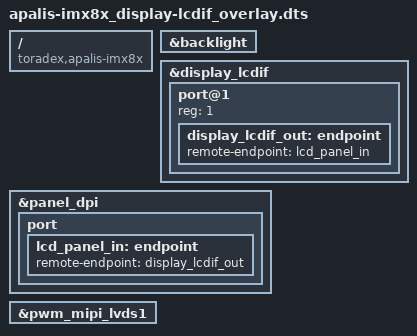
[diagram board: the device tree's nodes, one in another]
// SPDX-License-Identifier: GPL-2.0-or-later OR MIT
/*
 * Copyright 2020-2021 Toradex
 */

// Enable the parallel RGB interface on Apalis iMX8X using DPU-enabled driver

/dts-v1/;
/plugin/;

/ {
	compatible = "toradex,apalis-imx8x";
};

&backlight {
	status = "okay";
};

&display_lcdif {
	status = "okay";
	#address-cells = <1>;
	#size-cells = <0>;

	port@1 {
		reg = <1>;

		display_lcdif_out: endpoint {
			remote-endpoint = <&lcd_panel_in>;
		};
	};
};

&panel_dpi {
	status = "okay";

	port {
		lcd_panel_in: endpoint {
			remote-endpoint = <&display_lcdif_out>;
		};
	};
};

/* Apalis BKL1_PWM */
&pwm_mipi_lvds1 {
	status = "okay";
};
